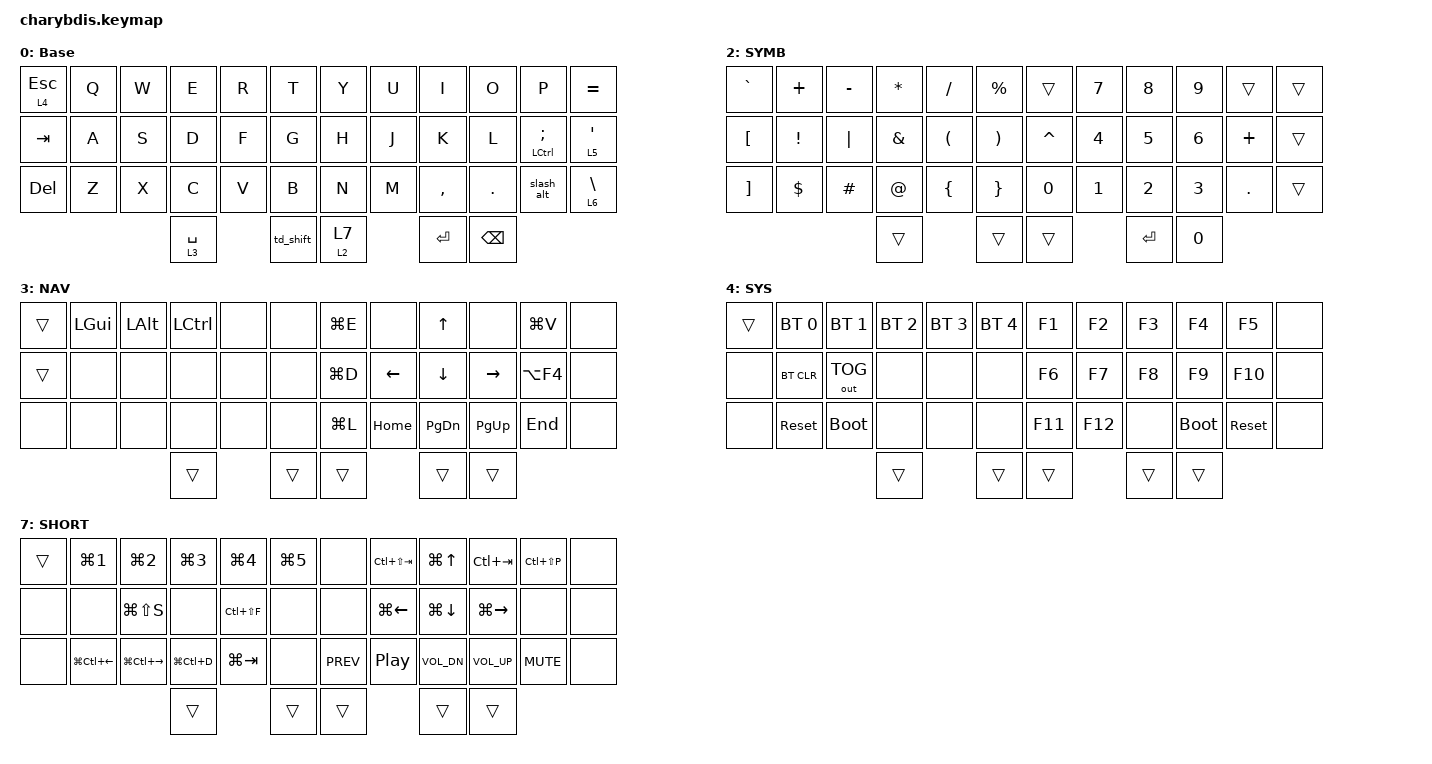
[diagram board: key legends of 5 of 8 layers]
#include <behaviors.dtsi>
#include <dt-bindings/zmk/mouse.h>
#include <dt-bindings/zmk/bt.h>
#include <dt-bindings/zmk/keys.h>
#include <dt-bindings/zmk/modifiers.h>
#include <dt-bindings/zmk/outputs.h>

/*
 * 层序：
 * 0 Base · 1 MOUSE · 2 SYMB · 3 NAV · 4 SYS · 5 SNIPE · 6 SCROLL · 7 SHORT
 *
 * 轨迹球模式由 charybdis_right.overlay 里的 input processors 按层匹配：
 * SNIPE(5)/SCROLL(6) 覆盖优先，否则 zip_temp_layer 临时开 MOUSE(1)。
 */

/*
 * 鼠标按键在 MOUSE / SNIPE / SCROLL 三层共用同一套布局，
 * 改这里就能三层同时生效，不必逐层手改。
 * 半排 = 6 键，顺序与 Base 层一致。
 */
#define MS_TRANS_6     &trans  &trans  &trans     &trans     &trans     &trans
// 右手中排: H  J=左键  K=中键  L=右键  ;=右键  '(SNIPE)
#define MS_HOME_R      &trans  &mkp LCLK  &mkp MCLK  &mkp RCLK  &mkp RCLK  &trans
// 右手下排: N  M  ,=左键  .=中键  /(Alt)  BSLH(SCROLL)
#define MS_BOTTOM_R    &trans  &trans  &mkp LCLK  &mkp MCLK  &trans     &trans

&lt {
    tapping-term-ms = <200>;
    flavor = "tap-preferred";
    quick-tap-ms = <180>;
};

/* 单点 MO 进入 SHORT 后，1.5 秒内没按键就自动退出 */
&sl {
    release-after-ms = <1500>;
};

/*
 * 键位编号（0 起，左→右、上→下）：
 *   左手 0-5 / 12-17 / 24-29，右手 6-11 / 18-23 / 30-35，拇指 36-40。
 */
#define KEYS_L      0 1 2 3 4 5 12 13 14 15 16 17 24 25 26 27 28 29
#define THUMBS      36 37 38 39 40

/ {
    behaviors {
        /*
         * 右手标点兼修饰（; = Ctrl，/ = Alt）。
         * 按住时按下左手键或拇指键 → 立刻判为修饰；按下右手键 → 判为点按。
         * 想配右手键（如 Ctrl+L），先按住超过 tapping-term 再按。
         * 刚连续打字（150ms 内）时直接当点按，避免误出修饰。
         */
        hmr: hold_tap_right_mod {
            compatible = "zmk,behavior-hold-tap";
            #binding-cells = <2>;
            flavor = "balanced";
            tapping-term-ms = <200>;
            quick-tap-ms = <180>;
            require-prior-idle-ms = <150>;
            hold-trigger-key-positions = <KEYS_L THUMBS>;
            hold-trigger-on-release;
            bindings = <&kp>, <&kp>;
        };

        /*
         * Shift + / 直接走普通按键，保留 Shift 输出问号。
         * 避免 / 超过 200ms 被判为 Alt，吞掉问号并误发 Alt+Shift 切换输入语言。
         * 不按 Shift 时仍是点按 /、长按 Alt；先按住 / 再加 Shift 仍可组合修饰键。
         */
        slash_alt: slash_alt {
            compatible = "zmk,behavior-mod-morph";
            #binding-cells = <0>;
            bindings = <&hmr LALT SLASH>, <&kp SLASH>;
            mods = <(MOD_LSFT | MOD_RSFT)>;
            keep-mods = <(MOD_LSFT | MOD_RSFT)>;
        };

        /*
         * Space 兼 NAV：balanced 下按住 Space 再完整点一下别的键才进 NAV，
         * 打字时 Space 与下一个字母重叠仍是空格；刚打过字时直接当空格。
         */
        lt_spc: layer_tap_space {
            compatible = "zmk,behavior-hold-tap";
            #binding-cells = <2>;
            flavor = "balanced";
            tapping-term-ms = <200>;
            quick-tap-ms = <180>;
            require-prior-idle-ms = <150>;
            bindings = <&mo>, <&kp>;
        };

        /*
         * 左拇指 Shift：单点 / 按住 = Shift（单点仍可切换输入法中英文），
         * 快速双击 = caps_word（下一个单词全大写，遇空格或标点自动退出）。
         */
        td_shift: tap_dance_shift {
            compatible = "zmk,behavior-tap-dance";
            #binding-cells = <0>;
            tapping-term-ms = <200>;
            bindings = <&kp LSHFT>, <&caps_word>;
        };

        /*
         * 左拇指 MO：按住 = SYMB；单点 = 一次性 SHORT 层（按一颗键后自动回 Base）。
         * hold-preferred：按住期间只要按了别的键就一定是 SYMB，打数字手感不变。
         */
        mo_sl: hold_mo_tap_sticky {
            compatible = "zmk,behavior-hold-tap";
            #binding-cells = <2>;
            flavor = "hold-preferred";
            tapping-term-ms = <200>;
            bindings = <&mo>, <&sl>;
        };
    };

    keymap {
        compatible = "zmk,keymap";

        Base {
            label = "Base";
            bindings = <
&lt 4 ESC  &kp Q  &kp W  &kp E  &kp R  &kp T        &kp Y  &kp U  &kp I      &kp O    &kp P          &kp EQUAL
&kp TAB    &kp A  &kp S  &kp D  &kp F  &kp G        &kp H  &kp J  &kp K      &kp L    &hmr LCTRL SEMI  &lt 5 SQT
&kp DEL    &kp Z  &kp X  &kp C  &kp V  &kp B        &kp N  &kp M  &kp COMMA  &kp DOT  &slash_alt       &lt 6 BSLH
                        &lt_spc 3 SPACE  &td_shift  &mo_sl 2 7        &kp RET  &kp BSPC
            >;
        };

        Mouse {
            label = "MOUSE";
            bindings = <
MS_TRANS_6        MS_TRANS_6
MS_TRANS_6        MS_HOME_R
MS_TRANS_6        MS_BOTTOM_R
                        &trans  &trans  &trans        &trans  &trans
            >;
        };

        Symb {
            label = "SYMB";
            bindings = <
&kp GRAVE &kp PLUS  &kp MINUS  &kp STAR  &kp SLASH  &kp PRCNT        &trans    &kp N7  &kp N8  &kp N9  &trans    &trans
&kp LBKT  &kp EXCL  &kp PIPE   &kp AMPS  &kp LPAR   &kp RPAR         &kp CARET &kp N4  &kp N5  &kp N6  &kp PLUS  &trans
&kp RBKT  &kp DLLR  &kp HASH   &kp AT    &kp LBRC   &kp RBRC         &kp N0    &kp N1  &kp N2  &kp N3  &kp DOT   &trans
                            &trans      &trans      &trans           &kp RET   &kp N0
            >;
        };

        Nav {
            label = "NAV";
            bindings = <
&trans  &kp LGUI  &kp LALT  &kp LCTRL  &none  &none        &kp LG(E)  &none     &kp UP    &none      &kp LG(V)  &none
&trans  &none     &none     &none      &none  &none        &kp LG(D)  &kp LEFT  &kp DOWN  &kp RIGHT  &kp LA(F4) &none
&none   &none     &none     &none      &none  &none        &kp LG(L)  &kp HOME  &kp PG_DN &kp PG_UP  &kp END    &none
                          &trans      &trans  &trans        &trans    &trans
            >;
        };

        Sys {
            label = "SYS";
            bindings = <
&trans  &bt BT_SEL 0  &bt BT_SEL 1  &bt BT_SEL 2  &bt BT_SEL 3  &bt BT_SEL 4        &kp F1  &kp F2  &kp F3  &kp F4  &kp F5  &none
&none   &bt BT_CLR    &out OUT_TOG  &none         &none         &none               &kp F6  &kp F7  &kp F8  &kp F9  &kp F10 &none
&none   &sys_reset    &bootloader   &none         &none         &none               &kp F11 &kp F12 &none   &bootloader &sys_reset &none
                                      &trans        &trans        &trans             &trans  &trans
            >;
        };

        Snipe {
            label = "SNIPE";
            bindings = <
MS_TRANS_6        MS_TRANS_6
MS_TRANS_6        MS_HOME_R
MS_TRANS_6        MS_BOTTOM_R
                        &trans  &trans  &trans        &trans  &trans
            >;
        };

        Scroll {
            label = "SCROLL";
            bindings = <
MS_TRANS_6        MS_TRANS_6
MS_TRANS_6        MS_HOME_R
MS_TRANS_6        MS_BOTTOM_R
                        &trans  &trans  &trans        &trans  &trans
            >;
        };

        /*
         * 单点 MO 进入，按一颗键后自动回 Base。按字母联想摆放：
         * 左上 Win+1~5；S 截图；F 全局搜索；左下虚拟桌面左/右/新建/任务视图；
         * 右手 IJKL 窗口贴靠（与 NAV 方向一致）；U/O 上/下一个标签；P 命令面板；
         * 右下 上一曲/播放暂停/音量-/音量+/静音。
         * Esc 位和拇指透传：点错时按 Esc 取消，或等 1.5 秒自动退出。
         */
        Short {
            label = "SHORT";
            bindings = <
&trans  &kp LG(N1)       &kp LG(N2)        &kp LG(N3)      &kp LG(N4)     &kp LG(N5)        &none        &kp LC(LS(TAB))  &kp LG(UP)    &kp LC(TAB)    &kp LC(LS(P))  &none
&none   &none            &kp LG(LS(S))     &none           &kp LC(LS(F))  &none             &none        &kp LG(LEFT)     &kp LG(DOWN)  &kp LG(RIGHT)  &none          &none
&none   &kp LG(LC(LEFT)) &kp LG(LC(RIGHT)) &kp LG(LC(D))   &kp LG(TAB)    &none             &kp C_PREV   &kp C_PP         &kp C_VOL_DN  &kp C_VOL_UP   &kp C_MUTE     &none
                                           &trans          &trans         &trans            &trans       &trans
            >;
        };
    };
};
